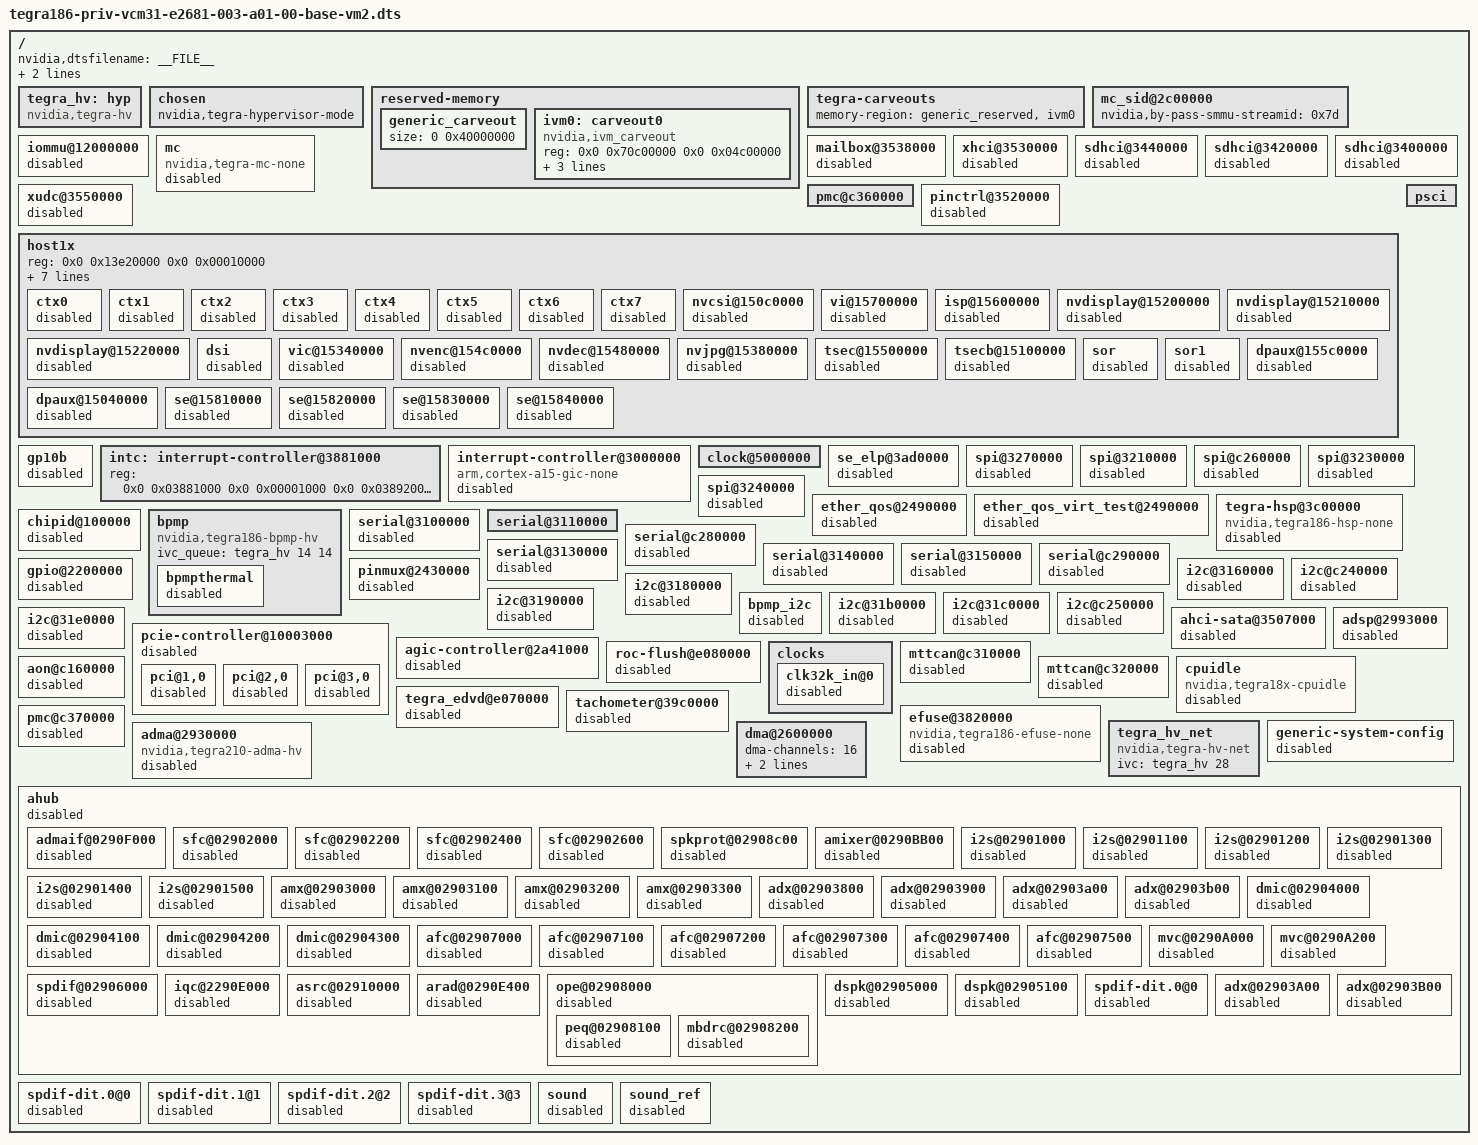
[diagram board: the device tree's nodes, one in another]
/*
 * tegra186-priv-vcm31-e2681-003-a01-00-base-vm2.dts: E2681 A01 base vm2 dts
 * file
 *
 * Copyright (c) 2016, NVIDIA CORPORATION.  All rights reserved.
 *
 * This program is free software; you can redistribute it and/or modify
 * it under the terms of the GNU General Public License as published by
 * the Free Software Foundation; version 2 of the License.
 *
 * This program is distributed in the hope that it will be useful, but WITHOUT
 * ANY WARRANTY; without even the implied warranty of MERCHANTABILITY or
 * FITNESS FOR A PARTICULAR PURPOSE.  See the GNU General Public License for
 * more details.
 */

#include "tegra186-platforms/tegra186-vcm31-e2681-common.dtsi"
#include "t186-status-override/tegra186-vcm31-e2681-0003-a01-dt-status-override.dtsi"
#include "tegra186-platforms/tegra186-vcm31-camera-ccplex.dtsi"

/ {
	nvidia,dtsfilename = __FILE__;
	nvidia,boardids = "e2681:0003:A01";
	nvidia,proc-boardid = "e2681:0003:A01";

	tegra_hv: hyp {
		compatible = "nvidia,tegra-hv";
		status = "okay";
	};

	chosen {
		nvidia,tegra-hypervisor-mode;
	};

	reserved-memory {
		generic_carveout {
			status = "okay";
			size = <0 0x40000000>;
		};

		ivm0: carveout0 {
			status = "okay";
			compatible = "nvidia,ivm_carveout";
			reg = <0x0 0x70c00000 0x0 0x04c00000>;
			ivm = <&tegra_hv 0>;
			alloc = <1>;
			no-map;
		};
	};

	tegra-carveouts {
		status = "okay";
		memory-region = <&generic_reserved &ivm0>;
	};

	mc_sid@2c00000 {
		nvidia,by-pass-smmu-streamid = <0x7d>;
		status = "okay";
	};

	iommu@12000000 {
		status = "disabled";
	};

	mc {
		compatible = "nvidia,tegra-mc-none";
		status = "disabled";
        };

	mailbox@3538000 {
		status = "disabled";
	};

	xhci@3530000 {
		status = "disabled";
	};

	sdhci@3440000 {
		status = "disabled";
	};

	sdhci@3420000 { /* Should be used for eMMC. HS400 mode is not supported */
		status = "disabled";
	};

	sdhci@3400000 {
		status = "disabled";
	};

	xudc@3550000 {
		status = "disabled";
	};

	pmc@c360000 {
		status = "okay";
	};

	pinctrl@3520000 {
		status = "disabled";
	};

	host1x {
		reg = <0x0 0x13e20000 0x0 0x00010000>;
		interrupts = <0 266 0x04
					0 263 0x04>;
		nvidia,vmid = <2>;

		nvidia,ch-base = <32>;
		nvidia,nb-channels = <30>;

		nvidia,nb-hw-pts = <576>;
		nvidia,pts-base = <288>;
		nvidia,nb-pts = <288>;

		ctx0 {
			status = "disabled";
		};

		ctx1 {
			status = "disabled";
		};

		ctx2 {
			status = "disabled";
		};

		ctx3 {
			status = "disabled";
		};

		ctx4 {
			status = "disabled";
		};

		ctx5 {
			status = "disabled";
		};

		ctx6 {
			status = "disabled";
		};

		ctx7 {
			status = "disabled";
		};

		nvcsi@150c0000 {
			status = "disabled";
		};

		vi@15700000 {
			status = "disabled";
		};

		isp@15600000 {
			status = "disabled";
		};

		nvdisplay@15200000 {
			status = "disabled";
		};

		nvdisplay@15210000 {
			status = "disabled";
		};

		nvdisplay@15220000 {
			status = "disabled";
		};

		dsi {
			status = "disabled";
		};

		vic@15340000 {
			status = "disabled";
		};

		nvenc@154c0000 {
			status = "disabled";
		};

		nvdec@15480000 {
			status = "disabled";
		};

		nvjpg@15380000 {
			status = "disabled";
		};

		tsec@15500000 {
			status = "disabled";
		};

		tsecb@15100000 {
			status = "disabled";
		};

		sor {
			status = "disabled";
		};

		sor1 {
			status = "disabled";
		};

		dpaux@155c0000 {
			status = "disabled";
		};

		dpaux@15040000 {
			status = "disabled";
		};

		se@15810000 {
			status = "disabled";
		};

		se@15820000 {
			status = "disabled";
		};

		se@15830000 {
			status = "disabled";
		};

		se@15840000 {
			status = "disabled";
		};
	};

	gp10b {
		status = "disabled";
	};

	psci {
		status = "okay";
	};

	interrupt-controller@3881000 {
		status = "okay";
	};

	interrupt-controller@3000000 {
		compatible = "arm,cortex-a15-gic-none";
		status = "disabled";
	};

	clock@5000000 {
		status = "okay";
	};

	se_elp@3ad0000 {
		status = "disabled";
	};

	spi@3270000 {
		status = "disabled";
	};

	spi@3210000 {
		status = "disabled";
	};

	spi@c260000 {
		status = "disabled";
	};

	spi@3230000 {
		status = "disabled";
	};

	spi@3240000 {
		status = "disabled";
	};

        ether_qos@2490000 {
		status = "disabled";
        };

        ether_qos_virt_test@2490000 {
		status = "disabled";
        };

	tegra-hsp@3c00000 {
		compatible = "nvidia,tegra186-hsp-none";
		status = "disabled";
	};

	chipid@100000 {
		status = "disabled";
	};

	bpmp {
		compatible = "nvidia,tegra186-bpmp-hv";
		ivc_queue = <&tegra_hv 14 14>;
		status = "okay";

		bpmpthermal {
			status = "disabled";
		};
	};

	serial@3100000 {
		status = "disabled";
	};

	serial@3110000 {
		status = "okay";
	};

	serial@c280000 {
		status = "disabled";
	};

	serial@3130000 {
		status = "disabled";
	};

	serial@3140000 {
		status = "disabled";
	};

	serial@3150000 {
		status = "disabled";
	};

	serial@c290000 {
		status = "disabled";
	};

	pinmux@2430000 {
                status = "disabled";
        };

        gpio@2200000 {
                status = "disabled";
        };

	i2c@3160000 {
		status = "disabled";
	};

	i2c@c240000 {
		status = "disabled";
	};

	i2c@3180000 {
		status = "disabled";
	};

	i2c@3190000 {
		status = "disabled";
	};

	bpmp_i2c {
		status = "disabled";
	};

	i2c@31b0000 {
		status = "disabled";
	};

	i2c@31c0000 {
		status = "disabled";
	};

	i2c@c250000 {
		status = "disabled";
	};

	i2c@31e0000 {
		status = "disabled";
	};

	ahci-sata@3507000 {
		status = "disabled";
	};

	pcie-controller@10003000 {
		status = "disabled";

		pci@1,0 {
			status = "disabled";
		};

		pci@2,0 {
			status = "disabled";
		};

		pci@3,0 {
			status = "disabled";
		};

	};

	agic-controller@2a41000 {
		status = "disabled";
	};

	adsp@2993000 {
		status = "disabled";
	};

	roc-flush@e080000 {
		status = "disabled";
	};

	clocks {
	     clk32k_in@0 {
		status = "disabled";
	     };
	};

	mttcan@c310000 {
		status = "disabled";
	};

	mttcan@c320000 {
		status = "disabled";
	};

	cpuidle {
		compatible = "nvidia,tegra18x-cpuidle";
		status = "disabled";
	};

	tegra_edvd@e070000 {
		status = "disabled";
	};

	aon@c160000 {
		status = "disabled";
	};

	efuse@3820000 {
                compatible = "nvidia,tegra186-efuse-none";
		status = "disabled";
	};

	tachometer@39c0000 {
		status = "disabled";
	};

	tegra_hv_net {
		compatible = "nvidia,tegra-hv-net";
		status = "okay";
		ivc = <&tegra_hv 28>;
	};

	pmc@c370000 {
		status = "disabled";
	};

	generic-system-config {
		status = "dislabled";
	};

	dma@2600000 {
		dma-channels = <16>;
		nvidia,start-dma-channel-index = <16>;
		nvidia,stream-id = <TEGRA_SID_GPCDMA_1>;
		status = "okay";
	};

	intc: interrupt-controller@3881000 {
		reg = <0x0 0x03881000 0x0 0x00001000
		       0x0 0x03892000 0x0 0x00002000>;
	};

	adma@2930000 {
		compatible = "nvidia,tegra210-adma-hv";
		status = "disabled";
	};

	ahub {
		status = "disabled";

		admaif@0290F000 {
			status = "disabled";
		};

		sfc@02902000 {
			status = "disabled";
		};

		sfc@02902200 {
			status = "disabled";
		};

		sfc@02902400 {
			status = "disabled";
		};

		sfc@02902600 {
			status = "disabled";
		};

		spkprot@02908c00 {
			status = "disabled";
		};

		amixer@0290BB00 {
			status = "disabled";
		};

		i2s@02901000 {
			status = "disabled";
		};

		i2s@02901100 {
			status = "disabled";
		};

		i2s@02901200 {
			status = "disabled";
		};

		i2s@02901300 {
			status = "disabled";
		};

		i2s@02901400 {
			status = "disabled";
		};

		i2s@02901500 {
			status = "disabled";
		};

		amx@02903000 {
			status = "disabled";
		};

		amx@02903100 {
			status = "disabled";
		};

		amx@02903200 {
			status = "disabled";
		};

		amx@02903300 {
			status = "disabled";
		};

		adx@02903800 {
			status = "disabled";
		};

		adx@02903900 {
			status = "disabled";
		};

		adx@02903a00 {
			status = "disabled";
		};

		adx@02903b00 {
			status = "disabled";
		};

		dmic@02904000 {
			status = "disabled";
		};

		dmic@02904100 {
			status = "disabled";
		};

		dmic@02904200 {
			status = "disabled";
		};

		dmic@02904300 {
			status = "disabled";
		};

		afc@02907000 {
			status = "disabled";
		};

		afc@02907100 {
			status = "disabled";
		};

		afc@02907200 {
			status = "disabled";
		};

		afc@02907300 {
			status = "disabled";
		};

		afc@02907400 {
			status = "disabled";
		};

		afc@02907500 {
			status = "disabled";
		};

		mvc@0290A000 {
			status = "disabled";
		};

		mvc@0290A200 {
			status = "disabled";
		};

		spdif@02906000 {
			status = "disabled";
		};

		iqc@2290E000 {
			status = "disabled";
		};

		asrc@02910000 {
			status = "disabled";
		};

		arad@0290E400 {
			status = "disabled";
		};

		ope@02908000 {
			status = "disabled";

			peq@02908100 {
				status = "disabled";
			};

			mbdrc@02908200 {
				status = "disabled";
			};
		};

		dspk@02905000 {
			status = "disabled";
		};

		dspk@02905100 {
			status = "disabled";
		};

		spdif-dit.0@0 {
			status = "disabled";
		};

		adx@02903A00 {
			status = "disabled";
		};

		adx@02903B00 {
			status = "disabled";
		};
	};

	spdif-dit.0@0 {
		status = "disabled";
	};

	spdif-dit.1@1 {
		status = "disabled";
	};

	spdif-dit.2@2 {
		status = "disabled";
	};

	spdif-dit.3@3 {
		status = "disabled";
	};

	sound {
		status = "disabled";
	};

	sound_ref {
		status = "disabled";
	};
};
